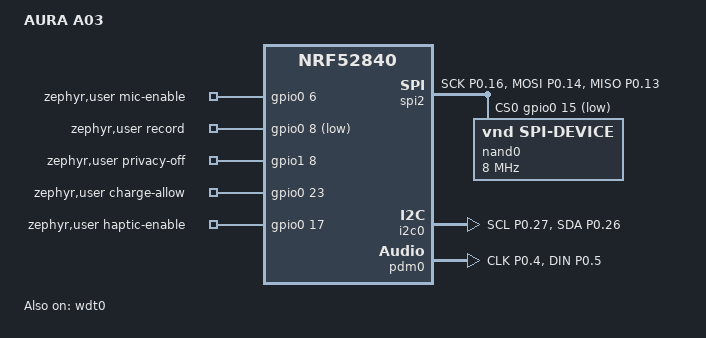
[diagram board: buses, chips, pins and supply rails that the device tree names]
/dts-v1/;
#include <nordic/nrf52840_qiaa.dtsi>
#include <zephyr/dt-bindings/gpio/gpio.h>
#include <zephyr/dt-bindings/pinctrl/nrf-pinctrl.h>
/ {
 model = "AURA A03";
 compatible = "aura,a03";
 chosen { zephyr,sram = &sram0; zephyr,flash = &flash0; zephyr,code-partition = &app_partition; };
 zephyr,user {
  mic-enable-gpios = <&gpio0 6 GPIO_ACTIVE_HIGH>;
  record-gpios = <&gpio0 8 (GPIO_PULL_UP | GPIO_ACTIVE_LOW)>;
  privacy-off-gpios = <&gpio1 8 (GPIO_PULL_UP | GPIO_ACTIVE_HIGH)>;
  charge-allow-gpios = <&gpio0 23 GPIO_ACTIVE_HIGH>;
  haptic-enable-gpios = <&gpio0 17 GPIO_ACTIVE_HIGH>;
 };
};
&gpio0 {status = "okay";};
&gpio1 {status = "okay";};
&gpiote {status = "okay";};
&wdt0 {status = "okay";};
&uicr {gpio-as-nreset;};
&pinctrl {
 spi_default: spi_default {group1 {psels = <NRF_PSEL(SPIM_SCK,0,16)>, <NRF_PSEL(SPIM_MOSI,0,14)>, <NRF_PSEL(SPIM_MISO,0,13)>;};};
 spi_sleep: spi_sleep {group1 {psels = <NRF_PSEL(SPIM_SCK,0,16)>, <NRF_PSEL(SPIM_MOSI,0,14)>, <NRF_PSEL(SPIM_MISO,0,13)>;low-power-enable;};};
 i2c_default: i2c_default {group1 {psels = <NRF_PSEL(TWIM_SCL,0,27)>, <NRF_PSEL(TWIM_SDA,0,26)>;};};
 i2c_sleep: i2c_sleep {group1 {psels = <NRF_PSEL(TWIM_SCL,0,27)>, <NRF_PSEL(TWIM_SDA,0,26)>;low-power-enable;};};
 pdm_default: pdm_default {group1 {psels = <NRF_PSEL(PDM_CLK,0,4)>, <NRF_PSEL(PDM_DIN,0,5)>;};};
 pdm_sleep: pdm_sleep {group1 {psels = <NRF_PSEL(PDM_CLK,0,4)>, <NRF_PSEL(PDM_DIN,0,5)>;low-power-enable;};};
};
&spi2 {
 compatible = "nordic,nrf-spim";
 status = "okay";
 pinctrl-0 = <&spi_default>; pinctrl-1 = <&spi_sleep>; pinctrl-names = "default", "sleep";
 cs-gpios = <&gpio0 15 GPIO_ACTIVE_LOW>;
 nand0: nand@0 {compatible = "vnd,spi-device";reg = <0>;spi-max-frequency = <8000000>;};
};
&i2c0 {
 compatible = "nordic,nrf-twim"; status = "okay";
 pinctrl-0 = <&i2c_default>; pinctrl-1 = <&i2c_sleep>; pinctrl-names = "default", "sleep";
};
&pdm0 {status = "okay";pinctrl-0 = <&pdm_default>;pinctrl-1 = <&pdm_sleep>;pinctrl-names = "default", "sleep";};
&flash0 {
 partitions {compatible = "fixed-partitions";#address-cells = <1>;#size-cells = <1>;
  app_partition: partition@0 {label = "image-0";reg = <0x00000000 0x000f8000>;};
  storage_partition: partition@f8000 {label = "storage";reg = <0x000f8000 0x00008000>;};
 };
};
